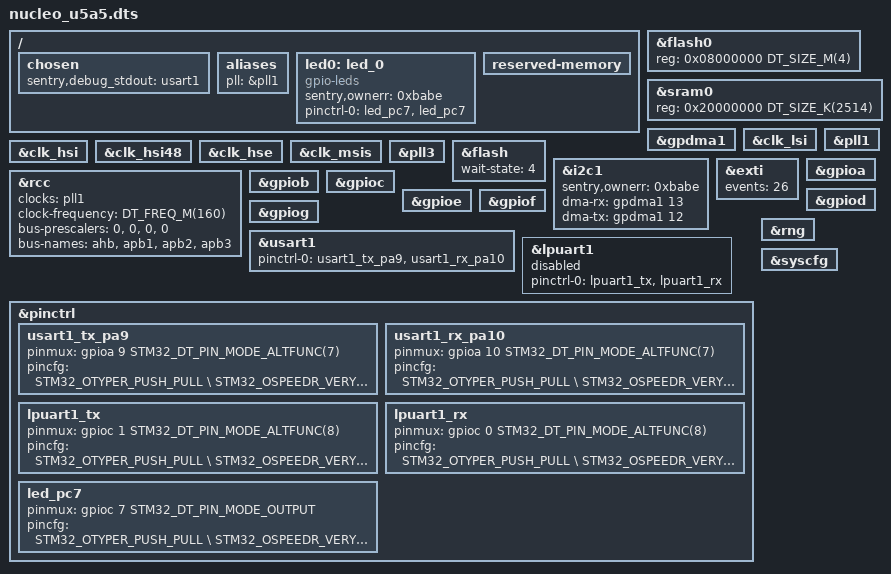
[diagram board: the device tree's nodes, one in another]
/*
 * Copyright (c) 2023,Ledger SAS
 *
 * SPDX-License-Identifier: Apache-2.0
 */

/dts-v1/;

#include <st/u5/stm32u595.dtsi>
#include <dt-bindings/pinctrl/stm32-pinctrl.h>
#include <sentry.dtsi>

/{
	chosen {
		sentry,debug_stdout = <&usart1>;
	};

	aliases {
        pll = &pll1;
    };

	led0: led_0 {
		compatible = "gpio-leds";
		sentry,ownerr = <0xbabe>;
		pinctrl-0 = <&led_pc7 &led_pc7>;
		status = "disabled";
	};
};

/{
	reserved-memory {
	};

};

&led0 {
	status = "okay";
};

&flash0 {
	reg = <0x08000000 DT_SIZE_M(4)>;
};

&sram0 {
	reg = <0x20000000 DT_SIZE_K(2514)>;
};

&gpdma1 {
	status = "okay";
};

&clk_lsi {
	status = "okay";
};

&clk_hsi {
	status = "okay";
};

&clk_hsi48 {
       status = "okay";
};

&clk_hse {
	status = "okay";
};

&clk_msis {
	status = "okay";
};

&pll1 {
	status = "okay";
};

&pll3 {
	status = "okay";
};

&flash {
	wait-state = <4>; /* According to voltage supply and sysclock */
	status = "okay";
};

&i2c1 {
	status = "okay";
	sentry,ownerr = <0xbabe>;
	dma-rx = <&gpdma1 13>;
	dma-tx = <&gpdma1 12>;
};

&rcc {
	clocks = <&pll1>;
	clock-frequency = <DT_FREQ_M(160)>;
	bus-prescalers = <0>, <0>, <0>, <0>;
	bus-names = "ahb", "apb1", "apb2", "apb3";
	status = "okay";
};

&exti {
	events = <26>;
	status = "okay";
};

&gpioa {
	status = "okay";
};

&gpiob {
	status = "okay";
};

&gpioc {
	status = "okay";
};

&gpiod {
	status = "okay";
};

&gpioe {
	status = "okay";
};

&gpiof {
	status = "okay";
};

&gpiog {
	status = "okay";
};

&usart1{
	status = "okay";
	pinctrl-0 = <&usart1_tx_pa9>, <&usart1_rx_pa10>;
};

&lpuart1{
	status = "disabled";
	pinctrl-0 = <&lpuart1_tx>, <&lpuart1_rx>;
};

&pinctrl {
	usart1_tx_pa9: usart1_tx_pa9  {
		pinmux = <&gpioa 9 STM32_DT_PIN_MODE_ALTFUNC(7)>;
		pincfg = <STM32_OTYPER_PUSH_PULL \
				  STM32_OSPEEDR_VERY_HIGH_SPEED \
				  STM32_PUPDR_NO_PULL>;
	};

	usart1_rx_pa10: usart1_rx_pa10  {
		pinmux = <&gpioa 10 STM32_DT_PIN_MODE_ALTFUNC(7)>;
		pincfg = <STM32_OTYPER_PUSH_PULL \
				  STM32_OSPEEDR_VERY_HIGH_SPEED \
				  STM32_PUPDR_NO_PULL>;
	};

	lpuart1_tx: lpuart1_tx  {
		pinmux = <&gpioc 1 STM32_DT_PIN_MODE_ALTFUNC(8)>;
		pincfg = <STM32_OTYPER_PUSH_PULL \
				  STM32_OSPEEDR_VERY_HIGH_SPEED \
				  STM32_PUPDR_NO_PULL>;
	};

	lpuart1_rx: lpuart1_rx  {
		pinmux = <&gpioc 0 STM32_DT_PIN_MODE_ALTFUNC(8)>;
		pincfg = <STM32_OTYPER_PUSH_PULL \
				  STM32_OSPEEDR_VERY_HIGH_SPEED \
				  STM32_PUPDR_NO_PULL>;
	};

	led_pc7: led_pc7 {
		pinmux = <&gpioc 7 STM32_DT_PIN_MODE_OUTPUT>;
		pincfg = <STM32_OTYPER_PUSH_PULL \
				  STM32_OSPEEDR_VERY_HIGH_SPEED \
				  STM32_PUPDR_NO_PULL>;
	};
};

&rng {
	status = "okay";
};

&syscfg {
	status = "okay";
};
